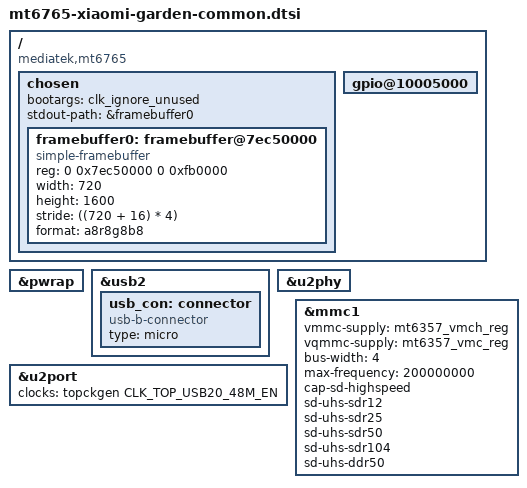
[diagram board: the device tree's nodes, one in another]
// SPDX-License-Identifier: (GPL-2.0 OR MIT)
/*
 * Copyright (c) 2023 Arseniy Velikanov <adomerlee@gmail.com>
 * Copyright (C) 2023 Brandon Boese
 */

#include "mt6765.dtsi"
#include "mt6765-bl-quirks.dtsi"
#include "mt6357.dtsi"

/ {
    compatible = "mediatek,mt6765";

    chosen {
        /*
         * FIXME: drop clk_ignore_unused, keeps getting watchdog rebooted without it for now!
         */
        bootargs = "clk_ignore_unused";

        stdout-path = &framebuffer0;

        /*
         * HACK: Use display framebuffer setup by the lk bootloader for simplefb
         * NOTE: only text is rendered on VT (TTY) as an unknown bit has to be flipped to disable
         *        image compression!
         */
        framebuffer0: framebuffer@7ec50000 {
            compatible = "simple-framebuffer";
            reg = <0 0x7ec50000 0 0xfb0000>;
            status = "okay";
            width = <720>;
            height = <1600>;
            stride = <((720 + 16) * 4)>;
            format = "a8r8g8b8";
        };
    };

    /* The following are required by stock bootloader to merge with minimal DTBO */
    gpio@10005000 {
        linux,phandle = <0xdead>;
        phandle = <0xdead>;
    };
    __symbols__ {
        gpio = "/gpio@10005000";
    };

};

&pwrap {
    status = "okay";
};

&usb2 {
    status = "okay";

    usb_con: connector {
        compatible = "usb-b-connector";
        type = "micro";
    };
};

&u2phy {
    status = "okay";
};

&u2port {
    clocks = <&topckgen CLK_TOP_USB20_48M_EN>;
};

&mmc1 {
    status = "okay";

    vmmc-supply = <&mt6357_vmch_reg>;
    vqmmc-supply = <&mt6357_vmc_reg>;

    bus-width = <4>;
    max-frequency = <200000000>;
    cap-sd-highspeed;
    sd-uhs-sdr12;
    sd-uhs-sdr25;
    sd-uhs-sdr50;
    sd-uhs-sdr104;
    sd-uhs-ddr50;
};
